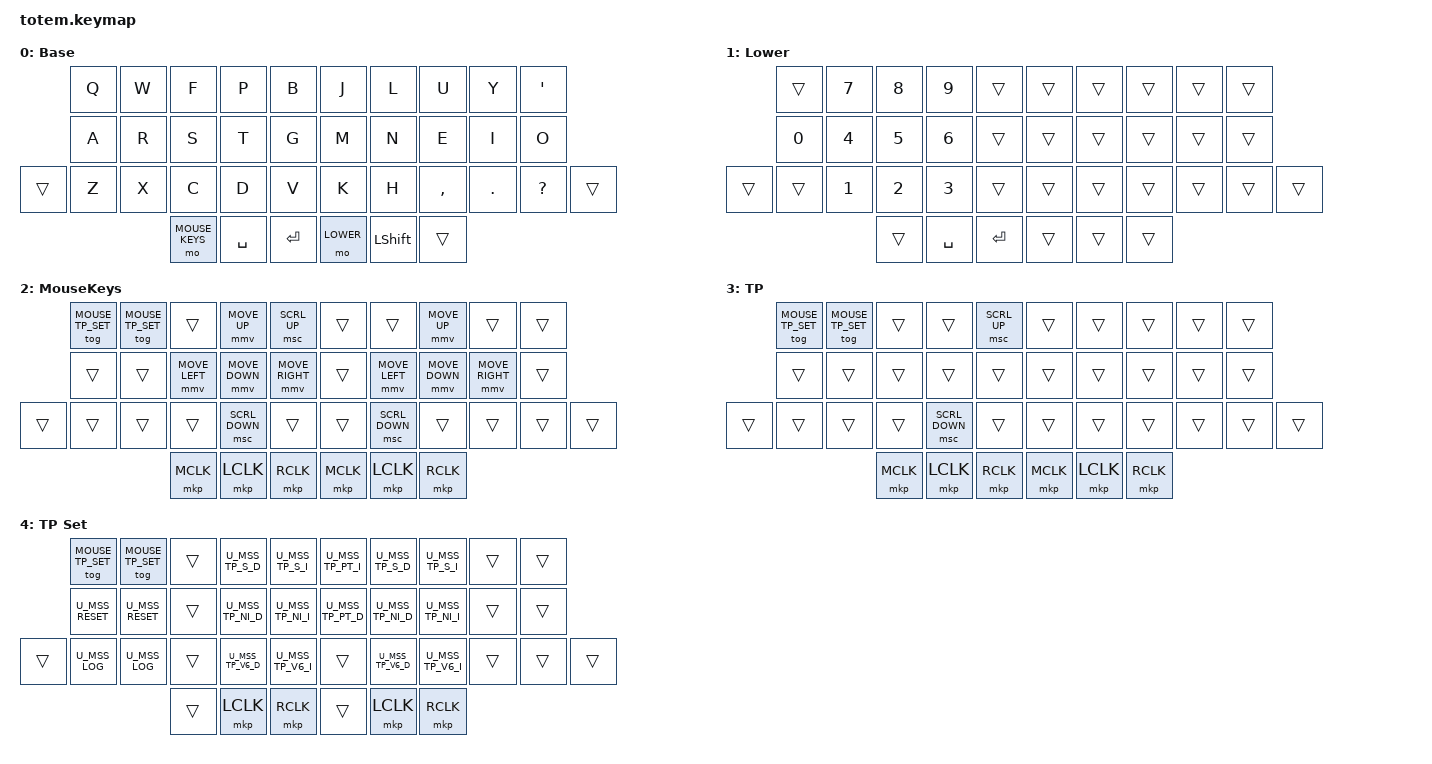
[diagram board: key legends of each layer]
#include <behaviors.dtsi>
#include <dt-bindings/zmk/keys.h>
#include <dt-bindings/zmk/bt.h>

#define BASE 0
#define LOWER 1
#define MOUSE_KEYS 2
#define MOUSE_TP 3
#define MOUSE_TP_SET 4

/*
 * Defines to enable/disable features
 *
 * These defines allow us to conditionally enable and disable parts of the keymap config.
 *
 * For example, if we decide to build the firmware without the mouse features, we can
 * disable all the config options that rely on those forks and modules without having
 * to edit the entire keymap file manually every time.
 */

#define HAS_MOUSE_KEYS
#define HAS_MOUSE_TP

#ifdef HAS_MOUSE_KEYS
  #include <dt-bindings/zmk/mouse.h>
  #include <behaviors/mouse_keys.dtsi>
#endif  // HAS_MOUSE_KEYS

#ifdef HAS_MOUSE_TP
  // We store the trackpoint settings in a separate file
  // to make organization a little easier.
  #include "include/mouse_tp.dtsi"
#endif  // HAS_MOUSE_TP



// Adjust layer keys based on enabled features.
//
// This prevents build errors when we build the firmware
// without the mouse keys PR or the TP module.
#ifdef HAS_MOUSE_KEYS
  #define U_THUMB_INNER &mo MOUSE_KEYS
#else
  #define U_THUMB_INNER &none
#endif  // HAS_MOUSE_KEYS

#ifdef HAS_MOUSE_TP
  #define U_TOG_TP_SET &tog MOUSE_TP_SET
#else
  #define U_TOG_TP_SET &none
#endif  // HAS_MOUSE_TP

/ {
        keymap {
                compatible = "zmk,keymap";

                /*
                 * DEFAULT LAYER (Base layer - your main typing layer)
                 * 
                 * KEYMAP STRUCTURE:
                 * - Each row is defined on a separate line
                 * - Keys are separated by spaces
                 * - The visual layout shows the physical key positions
                 * - To DISABLE a key: replace its binding with &trans (transparent/no-op)
                 * - To CHANGE a key: replace the key code (e.g., &kp Q becomes &kp Z)
                 * 
                 * COMMON KEY CODES:
                 * - &kp KEYNAME (e.g., &kp Q, &kp SPACE, &kp ENTER)
                 * - &mo LAYER_NUMBER (momentary layer switch)
                 * - &mt MODIFIER KEY (mod-tap: hold for modifier, tap for key)
                 * - &lt LAYER KEY (layer-tap: hold for layer, tap for key)
                 * - &trans (transparent - key does nothing)
                 * - &bt BT_SEL N (Bluetooth device selection)
                 */
                Base_layer {
                        display-name = "Base";
                        bindings = <
//                    ┏━━━━━━━━━━━━━━━━━━┳━━━━━━━━━━━━━━━━━━┳━━━━━━━━━━━━━━━━━━┳━━━━━━━━━━━━━━━━━━┳━━━━━━━━━━━━━━━━━━┓   ┏━━━━━━━━━━━━━━━━━━┳━━━━━━━━━━━━━━━━━━┳━━━━━━━━━━━━━━━━━━┳━━━━━━━━━━━━━━━━━━┳━━━━━━━━━━━━━━━━━━┓
                      &kp Q              &kp W              &kp F              &kp P              &kp B                  &kp J              &kp L              &kp U              &kp Y              &kp SQT
//                    ┣━━━━━━━━━━━━━━━━━━╋━━━━━━━━━━━━━━━━━━╋━━━━━━━━━━━━━━━━━━╋━━━━━━━━━━━━━━━━━━╋━━━━━━━━━━━━━━━━━━┫   ┣━━━━━━━━━━━━━━━━━━╋━━━━━━━━━━━━━━━━━━╋━━━━━━━━━━━━━━━━━━╋━━━━━━━━━━━━━━━━━━╋━━━━━━━━━━━━━━━━━━┫
                      &kp A              &kp R              &kp S              &kp T              &kp G                  &kp M              &kp N              &kp E              &kp I              &kp O
// ┏━━━━━━━━━━━━━━━━━━╋━━━━━━━━━━━━━━━━━━╋━━━━━━━━━━━━━━━━━━╋━━━━━━━━━━━━━━━━━━╋━━━━━━━━━━━━━━━━━━╋━━━━━━━━━━━━━━━━━━┫   ┣━━━━━━━━━━━━━━━━━━╋━━━━━━━━━━━━━━━━━━╋━━━━━━━━━━━━━━━━━━╋━━━━━━━━━━━━━━━━━━╋━━━━━━━━━━━━━━━━━━╋━━━━━━━━━━━━━━━━━━┓
   &trans             &kp Z              &kp X              &kp C              &kp D              &kp V                  &kp K              &kp H              &kp COMMA          &kp DOT            &kp QMARK           &trans
// ┗━━━━━━━━━━━━━━━━━━┻━━━━━━━━━━━━━━━━━━┻━━━━━━━━━━━━━━━━━━╋━━━━━━━━━━━━━━━━━━╋━━━━━━━━━━━━━━━━━━╋━━━━━━━━━━━━━━━━━━┫   ┣━━━━━━━━━━━━━━━━━━╋━━━━━━━━━━━━━━━━━━╋━━━━━━━━━━━━━━━━━━╋━━━━━━━━━━━━━━━━━━╋━━━━━━━━━━━━━━━━━━╋━━━━━━━━━━━━━━━━━━┛
                                                            U_THUMB_INNER      &kp SPACE          &kp ENTER              &mo LOWER          &kp LSHFT          &trans
//                                                          ┗━━━━━━━━━━━━━━━━━━┻━━━━━━━━━━━━━━━━━━┻━━━━━━━━━━━━━━━━━━┛   ┗━━━━━━━━━━━━━━━━━━┻━━━━━━━━━━━━━━━━━━┻━━━━━━━━━━━━━━━━━━┛
                        >;
                };

                Lower_layer {
                        display-name = "Lower";
                        bindings = <
//                    ┏━━━━━━━━━━━━━━━━━━┳━━━━━━━━━━━━━━━━━━┳━━━━━━━━━━━━━━━━━━┳━━━━━━━━━━━━━━━━━━┳━━━━━━━━━━━━━━━━━━┓   ┏━━━━━━━━━━━━━━━━━━┳━━━━━━━━━━━━━━━━━━┳━━━━━━━━━━━━━━━━━━┳━━━━━━━━━━━━━━━━━━┳━━━━━━━━━━━━━━━━━━┓
                      &trans             &kp NUMBER_7       &kp NUMBER_8       &kp NUMBER_9       &trans                 &trans             &trans             &trans             &trans             &trans
//                    ┣━━━━━━━━━━━━━━━━━━╋━━━━━━━━━━━━━━━━━━╋━━━━━━━━━━━━━━━━━━╋━━━━━━━━━━━━━━━━━━╋━━━━━━━━━━━━━━━━━━┫   ┣━━━━━━━━━━━━━━━━━━╋━━━━━━━━━━━━━━━━━━╋━━━━━━━━━━━━━━━━━━╋━━━━━━━━━━━━━━━━━━╋━━━━━━━━━━━━━━━━━━┫
                      &kp NUMBER_0       &kp NUMBER_4       &kp NUMBER_5       &kp NUMBER_6       &trans                 &trans             &trans             &trans             &trans             &trans
// ┏━━━━━━━━━━━━━━━━━━╋━━━━━━━━━━━━━━━━━━╋━━━━━━━━━━━━━━━━━━╋━━━━━━━━━━━━━━━━━━╋━━━━━━━━━━━━━━━━━━╋━━━━━━━━━━━━━━━━━━┫   ┣━━━━━━━━━━━━━━━━━━╋━━━━━━━━━━━━━━━━━━╋━━━━━━━━━━━━━━━━━━╋━━━━━━━━━━━━━━━━━━╋━━━━━━━━━━━━━━━━━━╋━━━━━━━━━━━━━━━━━━┓
   &trans             &trans             &kp NUMBER_1       &kp NUMBER_2       &kp NUMBER_3       &trans                 &trans             &trans             &trans             &trans             &trans              &trans
// ┗━━━━━━━━━━━━━━━━━━┻━━━━━━━━━━━━━━━━━━┻━━━━━━━━━━━━━━━━━━╋━━━━━━━━━━━━━━━━━━╋━━━━━━━━━━━━━━━━━━╋━━━━━━━━━━━━━━━━━━┫   ┣━━━━━━━━━━━━━━━━━━╋━━━━━━━━━━━━━━━━━━╋━━━━━━━━━━━━━━━━━━╋━━━━━━━━━━━━━━━━━━╋━━━━━━━━━━━━━━━━━━╋━━━━━━━━━━━━━━━━━━┛
                                                            &trans             &kp SPACE          &kp ENTER              &trans             &trans             &trans
//                                                          ┗━━━━━━━━━━━━━━━━━━┻━━━━━━━━━━━━━━━━━━┻━━━━━━━━━━━━━━━━━━┛   ┗━━━━━━━━━━━━━━━━━━┻━━━━━━━━━━━━━━━━━━┻━━━━━━━━━━━━━━━━━━┛    
                        >;
                };


#ifdef HAS_MOUSE_KEYS

                MouseKeys_layer {
                        display-name = "MouseKeys";
                        bindings = <
//                    ┏━━━━━━━━━━━━━━━━━━┳━━━━━━━━━━━━━━━━━━┳━━━━━━━━━━━━━━━━━━┳━━━━━━━━━━━━━━━━━━┳━━━━━━━━━━━━━━━━━━┓   ┏━━━━━━━━━━━━━━━━━━┳━━━━━━━━━━━━━━━━━━┳━━━━━━━━━━━━━━━━━━┳━━━━━━━━━━━━━━━━━━┳━━━━━━━━━━━━━━━━━━┓
                      U_TOG_TP_SET       U_TOG_TP_SET       &trans             &mmv MOVE_UP        &msc SCRL_UP           &trans             &trans             &mmv MOVE_UP        &trans             &trans
//                    ┣━━━━━━━━━━━━━━━━━━╋━━━━━━━━━━━━━━━━━━╋━━━━━━━━━━━━━━━━━━╋━━━━━━━━━━━━━━━━━━╋━━━━━━━━━━━━━━━━━━┫   ┣━━━━━━━━━━━━━━━━━━╋━━━━━━━━━━━━━━━━━━╋━━━━━━━━━━━━━━━━━━╋━━━━━━━━━━━━━━━━━━╋━━━━━━━━━━━━━━━━━━┫
                      &trans             &trans             &mmv MOVE_LEFT     &mmv MOVE_DOWN      &mmv MOVE_RIGHT         &trans             &mmv MOVE_LEFT     &mmv MOVE_DOWN      &mmv MOVE_RIGHT    &trans
// ┏━━━━━━━━━━━━━━━━━━╋━━━━━━━━━━━━━━━━━━╋━━━━━━━━━━━━━━━━━━╋━━━━━━━━━━━━━━━━━━╋━━━━━━━━━━━━━━━━━━╋━━━━━━━━━━━━━━━━━━┫   ┣━━━━━━━━━━━━━━━━━━╋━━━━━━━━━━━━━━━━━━╋━━━━━━━━━━━━━━━━━━╋━━━━━━━━━━━━━━━━━━╋━━━━━━━━━━━━━━━━━━╋━━━━━━━━━━━━━━━━━━┓
   &trans             &trans             &trans             &trans             &msc SCRL_DOWN      &trans                  &trans             &msc SCRL_DOWN     &trans             &trans             &trans              &trans
// ┗━━━━━━━━━━━━━━━━━━┻━━━━━━━━━━━━━━━━━━┻━━━━━━━━━━━━━━━━━━╋━━━━━━━━━━━━━━━━━━╋━━━━━━━━━━━━━━━━━━╋━━━━━━━━━━━━━━━━━━┫   ┣━━━━━━━━━━━━━━━━━━╋━━━━━━━━━━━━━━━━━━╋━━━━━━━━━━━━━━━━━━╋━━━━━━━━━━━━━━━━━━╋━━━━━━━━━━━━━━━━━━╋━━━━━━━━━━━━━━━━━━┛
                                                            &mkp MCLK          &mkp LCLK           &mkp RCLK               &mkp MCLK          &mkp LCLK          &mkp RCLK
//                                                          ┗━━━━━━━━━━━━━━━━━━┻━━━━━━━━━━━━━━━━━━┻━━━━━━━━━━━━━━━━━━┛   ┗━━━━━━━━━━━━━━━━━━┻━━━━━━━━━━━━━━━━━━┻━━━━━━━━━━━━━━━━━━┛
                        >;
                };

#endif

#ifdef HAS_MOUSE_TP

                MouseTP_layer {
                        display-name = "TP";
                        bindings = <
//                    ┏━━━━━━━━━━━━━━━━━━┳━━━━━━━━━━━━━━━━━━┳━━━━━━━━━━━━━━━━━━┳━━━━━━━━━━━━━━━━━━┳━━━━━━━━━━━━━━━━━━┓   ┏━━━━━━━━━━━━━━━━━━┳━━━━━━━━━━━━━━━━━━┳━━━━━━━━━━━━━━━━━━┳━━━━━━━━━━━━━━━━━━┳━━━━━━━━━━━━━━━━━━┓
                      U_TOG_TP_SET       U_TOG_TP_SET       &trans             &trans             &msc SCRL_UP           &trans             &trans             &trans             &trans             &trans
//                    ┣━━━━━━━━━━━━━━━━━━╋━━━━━━━━━━━━━━━━━━╋━━━━━━━━━━━━━━━━━━╋━━━━━━━━━━━━━━━━━━╋━━━━━━━━━━━━━━━━━━┫   ┣━━━━━━━━━━━━━━━━━━╋━━━━━━━━━━━━━━━━━━╋━━━━━━━━━━━━━━━━━━╋━━━━━━━━━━━━━━━━━━╋━━━━━━━━━━━━━━━━━━┫
                      &trans             &trans             &trans             &trans             &trans                  &trans             &trans             &trans             &trans             &trans
// ┏━━━━━━━━━━━━━━━━━━╋━━━━━━━━━━━━━━━━━━╋━━━━━━━━━━━━━━━━━━╋━━━━━━━━━━━━━━━━━━╋━━━━━━━━━━━━━━━━━━╋━━━━━━━━━━━━━━━━━━┫   ┣━━━━━━━━━━━━━━━━━━╋━━━━━━━━━━━━━━━━━━╋━━━━━━━━━━━━━━━━━━╋━━━━━━━━━━━━━━━━━━╋━━━━━━━━━━━━━━━━━━╋━━━━━━━━━━━━━━━━━━┓
   &trans             &trans             &trans             &trans             &msc SCRL_DOWN      &trans                  &trans             &trans             &trans             &trans             &trans              &trans
// ┗━━━━━━━━━━━━━━━━━━┻━━━━━━━━━━━━━━━━━━┻━━━━━━━━━━━━━━━━━━╋━━━━━━━━━━━━━━━━━━╋━━━━━━━━━━━━━━━━━━╋━━━━━━━━━━━━━━━━━━┫   ┣━━━━━━━━━━━━━━━━━━╋━━━━━━━━━━━━━━━━━━╋━━━━━━━━━━━━━━━━━━╋━━━━━━━━━━━━━━━━━━╋━━━━━━━━━━━━━━━━━━╋━━━━━━━━━━━━━━━━━━┛
                                                            &mkp MCLK          &mkp LCLK           &mkp RCLK               &mkp MCLK          &mkp LCLK          &mkp RCLK
//                                                          ┗━━━━━━━━━━━━━━━━━━┻━━━━━━━━━━━━━━━━━━┻━━━━━━━━━━━━━━━━━━┛   ┗━━━━━━━━━━━━━━━━━━┻━━━━━━━━━━━━━━━━━━┻━━━━━━━━━━━━━━━━━━┛
                        >;
                };

                MouseSettings_layer {
                        display-name = "TP Set";
                        bindings = <
//                    ┏━━━━━━━━━━━━━━━━━━┳━━━━━━━━━━━━━━━━━━┳━━━━━━━━━━━━━━━━━━┳━━━━━━━━━━━━━━━━━━┳━━━━━━━━━━━━━━━━━━┓   ┏━━━━━━━━━━━━━━━━━━┳━━━━━━━━━━━━━━━━━━┳━━━━━━━━━━━━━━━━━━┳━━━━━━━━━━━━━━━━━━┳━━━━━━━━━━━━━━━━━━┓
                      U_TOG_TP_SET       U_TOG_TP_SET       &trans             U_MSS_TP_S_D       U_MSS_TP_S_I           U_MSS_TP_PT_I      U_MSS_TP_S_D       U_MSS_TP_S_I       &trans             &trans
//                    ┣━━━━━━━━━━━━━━━━━━╋━━━━━━━━━━━━━━━━━━╋━━━━━━━━━━━━━━━━━━╋━━━━━━━━━━━━━━━━━━╋━━━━━━━━━━━━━━━━━━┫   ┣━━━━━━━━━━━━━━━━━━╋━━━━━━━━━━━━━━━━━━╋━━━━━━━━━━━━━━━━━━╋━━━━━━━━━━━━━━━━━━╋━━━━━━━━━━━━━━━━━━┫
                      U_MSS_RESET        U_MSS_RESET        &trans             U_MSS_TP_NI_D      U_MSS_TP_NI_I          U_MSS_TP_PT_D      U_MSS_TP_NI_D      U_MSS_TP_NI_I      &trans             &trans
// ┏━━━━━━━━━━━━━━━━━━╋━━━━━━━━━━━━━━━━━━╋━━━━━━━━━━━━━━━━━━╋━━━━━━━━━━━━━━━━━━╋━━━━━━━━━━━━━━━━━━╋━━━━━━━━━━━━━━━━━━┫   ┣━━━━━━━━━━━━━━━━━━╋━━━━━━━━━━━━━━━━━━╋━━━━━━━━━━━━━━━━━━╋━━━━━━━━━━━━━━━━━━╋━━━━━━━━━━━━━━━━━━╋━━━━━━━━━━━━━━━━━━┓
   &trans             U_MSS_LOG          U_MSS_LOG          &trans             U_MSS_TP_V6_D      U_MSS_TP_V6_I          &trans             U_MSS_TP_V6_D      U_MSS_TP_V6_I      &trans             &trans              &trans
// ┗━━━━━━━━━━━━━━━━━━┻━━━━━━━━━━━━━━━━━━┻━━━━━━━━━━━━━━━━━━╋━━━━━━━━━━━━━━━━━━╋━━━━━━━━━━━━━━━━━━╋━━━━━━━━━━━━━━━━━━┫   ┣━━━━━━━━━━━━━━━━━━╋━━━━━━━━━━━━━━━━━━╋━━━━━━━━━━━━━━━━━━╋━━━━━━━━━━━━━━━━━━╋━━━━━━━━━━━━━━━━━━╋━━━━━━━━━━━━━━━━━━┛
                                                            &trans             &mkp LCLK           &mkp RCLK               &trans             &mkp LCLK          &mkp RCLK
//                                                          ┗━━━━━━━━━━━━━━━━━━┻━━━━━━━━━━━━━━━━━━┻━━━━━━━━━━━━━━━━━━┛   ┗━━━━━━━━━━━━━━━━━━┻━━━━━━━━━━━━━━━━━━┻━━━━━━━━━━━━━━━━━━┛
                        >;
                };

        #endif
        };
};
